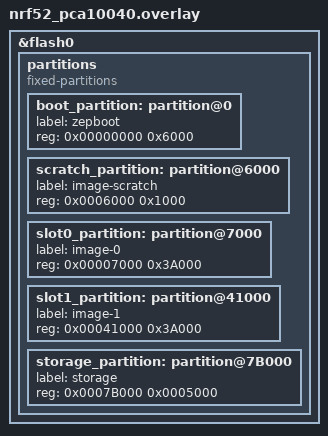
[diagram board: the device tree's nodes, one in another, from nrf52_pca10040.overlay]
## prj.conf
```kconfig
CONFIG_ZEPBOOT=y
CONFIG_ZEPBOOT_IS_BOOTLOADER=y
CONFIG_FLASH_LOAD_OFFSET=0x0
CONFIG_FLASH_SIZE=24

CONFIG_FLASH=y
CONFIG_FLASH_PAGE_LAYOUT=n

CONFIG_ENTROPY_GENERATOR=n
CONFIG_TINYCRYPT=y
CONFIG_TINYCRYPT_SHA256=y
CONFIG_TINYCRYPT_ECC_DH=y
CONFIG_TINYCRYPT_ECC_DSA=y
CONFIG_TINYCRYPT_AES=y
CONFIG_TINYCRYPT_AES_CTR=y

CONFIG_I2C=n
CONFIG_WATCHDOG=n
CONFIG_GPIO=n
CONFIG_PINMUX=n
CONFIG_SPI=n
CONFIG_SYS_POWER_MANAGEMENT=n
CONFIG_BT=n

CONFIG_ARM=y
CONFIG_ARM_MPU=n

CONFIG_BOOT_BANNER=n
CONFIG_BOOT_DELAY=0
CONFIG_DEBUG=n

# Console
CONFIG_LOG=y
CONFIG_LOG_MINIMAL=y
#CONFIG_CONSOLE=n
#CONFIG_EARLY_CONSOLE=n
#CONFIG_UART_CONSOLE=n
#CONFIG_STDOUT_CONSOLE=n
#CONFIG_PRINTK=n
#CONFIG_SERIAL=n

CONFIG_MULTITHREADING=n
CONFIG_NUM_PREEMPT_PRIORITIES=0
CONFIG_SYS_CLOCK_EXISTS=n
```

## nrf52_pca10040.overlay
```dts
/*
 * Copyright (c) 2019 Laczen
 *
 * SPDX-License-Identifier: Apache-2.0
 */

/delete-node/ &storage_partition;
/delete-node/ &slot0_partition;
/delete-node/ &slot1_partition;
/delete-node/ &scratch_partition;
/delete-node/ &boot_partition;

&flash0 {
	/*
	 * For more information, see:
	 * http://docs.zephyrproject.org/latest/guides/dts/index.html#flash-partitions
	 */
	partitions {
		compatible = "fixed-partitions";
		#address-cells = <1>;
		#size-cells = <1>;

		boot_partition: partition@0 {
			label = "zepboot";
			reg = <0x00000000 0x6000>;
		};
		scratch_partition: partition@6000 {
			label = "image-scratch";
			reg = <0x0006000 0x1000>;
		};
		slot0_partition: partition@7000 {
			label = "image-0";
			reg = <0x00007000 0x3A000>;
		};
		slot1_partition: partition@41000 {
			label = "image-1";
			reg = <0x00041000 0x3A000>;
		};
		storage_partition: partition@7B000 {
			label = "storage";
			reg = <0x0007B000 0x0005000>;
		};
	};
};
```

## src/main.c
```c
/*
 * Copyright (c) 2019 LaczenJMS.
 *
 * SPDX-License-Identifier: Apache-2.0
 */

#include <zephyr.h>
#include <misc/reboot.h>
#include <device.h>
#include <string.h>
#include <soc.h>
#include <zb_flash.h>
#include <zb_move.h>

#include <logging/log.h>
LOG_MODULE_REGISTER(main);

struct arm_vector_table {
    u32_t msp;
    u32_t reset;
};

static void do_boot(off_t load_address)
{
    struct arm_vector_table *vt;

    vt = (struct arm_vector_table *)(load_address);

    irq_lock();

    __set_MSP(vt->msp);
    ((void (*)(void))vt->reset)();
}

void main(void)
{
	int rc = 0, cnt;
	struct zb_slt_area area;
	struct zb_prm prm;
	struct zb_cmd cmd;
	zb_img_info info;
	u32_t crc32;

	cnt = zb_slt_area_cnt();

	/* Start or continue swap */
	while ((cnt--) > 0) {
		rc = zb_slt_area_get(&area, cnt);
		if (!rc) {
			rc = zb_img_swap(&area);
		}
	}

	/* Boot is done for images slot_map[0], area is already set OK */
	if (!rc) {
		rc = zb_prm_read(&area, &prm);
	}

	if (!rc) {
		zb_cmd_read_slt1end(&area, &cmd);
		if (cmd.cmd1 == CMD1_MASK_BT0_REQUEST) {
			prm.pri_ld_address = prm.sec_ld_address;
		}
	}

	/* Verify crc32 prior to boot */
	if ((!rc) && zb_in_slt_area(&area, 1, prm.pri_ld_address)) {
		zb_img_get_info_nsc(&info, &area, 1, 0, false);
		zb_img_calc_crc32(&info, &crc32);
		if (prm.slt1_crc32 != crc32) {
			prm.pri_ld_address = prm.sec_ld_address;
		}
	}

	if ((!rc) && (zb_in_slt_area(&area, 0, prm.pri_ld_address) ||
		      zb_in_ram(prm.pri_ld_address))) {
		zb_img_get_info_nsc(&info, &area, 0, 0, false);
		zb_img_calc_crc32(&info, &crc32);
		if (prm.slt0_crc32 != crc32) {
			rc = -EFAULT;
		}
		if ((!rc) && zb_in_ram(prm.pri_ld_address)) {
			rc = zb_img_ram_move(&info);
		}
	}

	if (!rc) {
		LOG_INF("Ready to boot [addr %x]", prm.pri_ld_address);
		/* boot */
		do_boot(prm.pri_ld_address);
	} else {
		LOG_ERR("Nothing valid to boot");
	}

}
```
